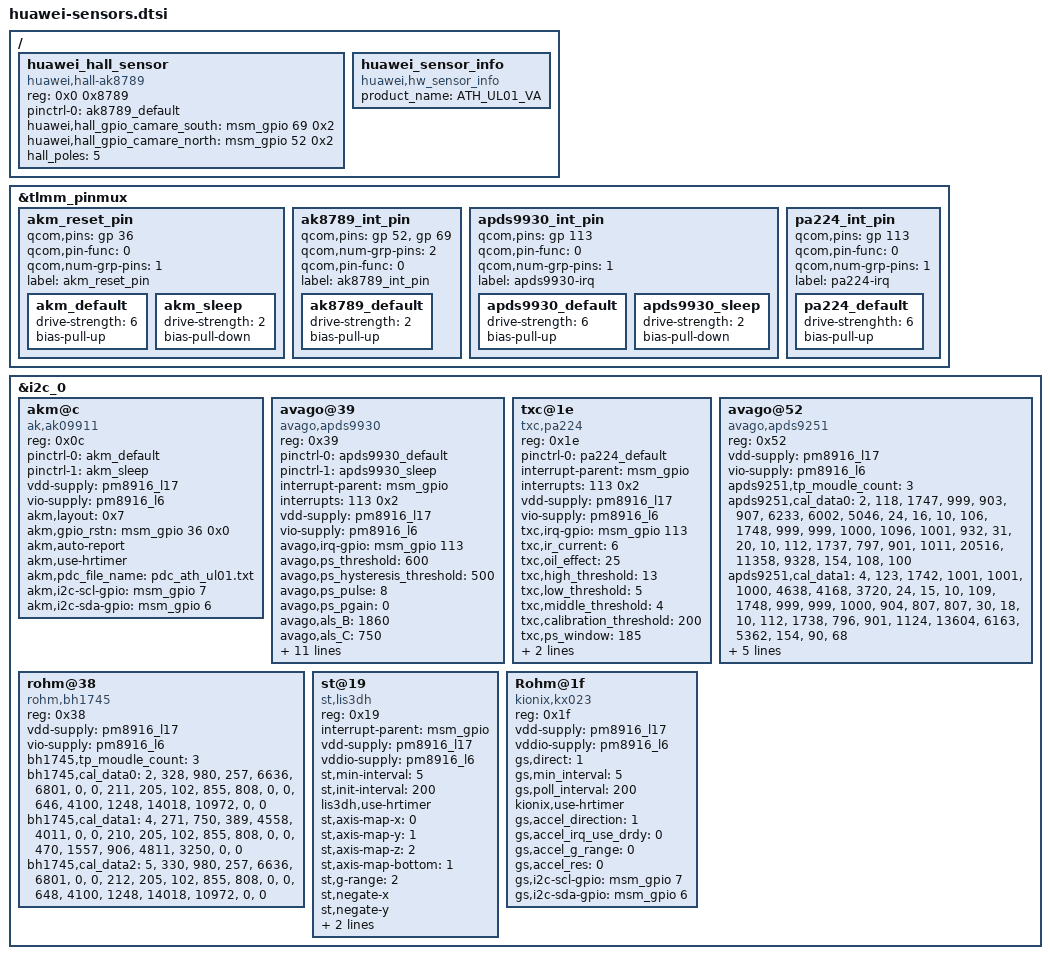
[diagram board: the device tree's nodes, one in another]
/*use fromdos convert file format to linux*/
/* Copyright (c) 2013 The Linux Foundation. All rights reserved.
 *
 * This program is free software; you can redistribute it and/or modify
 * it under the terms of the GNU General Public License version 2 and
 * only version 2 as published by the Free Software Foundation.
 *
 * This program is distributed in the hope that it will be useful,
 * but WITHOUT ANY WARRANTY; without even the implied warranty of
 * MERCHANTABILITY or FITNESS FOR A PARTICULAR PURPOSE.  See the
 * GNU General Public License for more details.
 */
&tlmm_pinmux {
	akm_reset_pin {
		qcom,pins = <&gp 36>;
		qcom,pin-func = <0>;
		qcom,num-grp-pins = <1>;
		label = "akm_reset_pin";
		akm_default: akm_default {
			drive-strength = <6>;
			bias-pull-up;
		};
		akm_sleep: akm_sleep {
			drive-strength = <2>;
			bias-pull-down;
		};
	};

	ak8789_int_pin {
		qcom,pins = <&gp 52>, <&gp 69>;
		qcom,num-grp-pins = <2>;
		qcom,pin-func = <0>;
		label = "ak8789_int_pin";
		ak8789_default: ak8789_default {
			  drive-strength = <2>;
			  bias-pull-up;
		};
	};
	apds9930_int_pin {
		qcom,pins = <&gp 113>;
		qcom,pin-func = <0>;
		qcom,num-grp-pins = <1>;
		label = "apds9930-irq";
		apds9930_default: apds9930_default {
			drive-strength = <6>;
			bias-pull-up;
		};
		apds9930_sleep: apds9930_sleep {
			drive-strength = <2>;
			bias-pull-down;
		};
	};
	pa224_int_pin {
		qcom,pins = <&gp 113>;
		qcom,pin-func = <0>;
		qcom,num-grp-pins = <1>;
		label = "pa224-irq";
		pa224_default: pa224_default {
			drive-strenghth = <6>;
			bias-pull-up;
		};
	};
};

&i2c_0 { /* BLSP1 QUP2 */
	akm@c {
		compatible = "ak,ak09911";
		reg = <0x0c>;
		pinctrl-names = "default","sleep";
		pinctrl-0 = <&akm_default>;
		pinctrl-1 = <&akm_sleep>;
		vdd-supply = <&pm8916_l17>;
		vio-supply = <&pm8916_l6>;
		akm,layout = <0x7>;
		akm,gpio_rstn = <&msm_gpio 36 0x0>;
		akm,auto-report;
		akm,use-hrtimer;
		akm,pdc_file_name = "pdc_ath_ul01.txt";
		akm,i2c-scl-gpio = <&msm_gpio 7 0x0>;
		akm,i2c-sda-gpio = <&msm_gpio 6 0x0>;
	};

	avago@39 {
		compatible = "avago,apds9930";
		reg = <0x39>;
		pinctrl-names = "default","sleep";
		pinctrl-0 = <&apds9930_default>;
		pinctrl-1 = <&apds9930_sleep>;
		interrupt-parent = <&msm_gpio>;
		interrupts = <113 0x2>;
		vdd-supply = <&pm8916_l17>;
		vio-supply = <&pm8916_l6>;
		avago,irq-gpio = <&msm_gpio 113 0x2>;
		avago,ps_threshold = <600>;
		avago,ps_hysteresis_threshold = <500>;
		avago,ps_pulse = <8>;
		avago,ps_pgain = <0>;
		avago,als_B = <1860>;
		avago,als_C = <750>;
		avago,als_D = <1290>;
		avago,ga_value = <48>;
	        avago,ga_a_value = <112>;
		avago,ga_c_value = <450>;
		avago,ga_d_value = <162>;
		avago,window = <110>;
		avago,wave = <84>;
		avago,ga_e_value = <220>;
		avago,ga_f_value = <43>;
		avago,i2c-scl-gpio = <&msm_gpio 7 0x0>;
		avago,i2c-sda-gpio = <&msm_gpio 6 0x0>;
	};
	txc@1e {
		compatible = "txc,pa224";
		reg = <0x1e>;
		pinctrl-names = "default";
		pinctrl-0 = <&pa224_default>;
		interrupt-parent = <&msm_gpio>;
		interrupts = <113 0x2>;
		vdd-supply = <&pm8916_l17>;
		vio-supply = <&pm8916_l6>;
		txc,irq-gpio = <&msm_gpio 113 0x2>;
		/*IR CURRENT 10MA*/
		txc,ir_current = <6>;
		txc,oil_effect = <25>;
		txc,high_threshold = <13>;
		txc,low_threshold = <5>;
		txc,middle_threshold = <4>;
		txc,calibration_threshold = <200>;
		txc,ps_window = <185>;
		txc,ps_wave = <20>;
		txc,ps_defalt_crosstalk = <50>;
	};
	avago@52 {
		compatible = "avago,apds9251";
		reg = <0x52>;
		vdd-supply = <&pm8916_l17>;
		vio-supply = <&pm8916_l6>;
		apds9251,tp_moudle_count = <3>;
		/*[module_id] [CCT_M] [CCT_N] [H] [A] [D] [LUX_P] [LUX_Q] [LUX_R] [cofficient0] [cofficient1] [cofficient2]*/
		apds9251,cal_data0 = "2","118","1747","999","903","907","6233","6002","5046","24","16","10",
		/*[CCT_M] [CCT_N] [H] [A] [D] [LUX_P] [LUX_Q] [LUX_R] [cofficient0] [cofficient1] [cofficient2]*/
		"106","1748","999","999","1000","1096","1001","932","31","20","10",
		/*[CCT_M] [CCT_N] [H] [A] [D] [LUX_P] [LUX_Q] [LUX_R] [cofficient0] [cofficient1] [cofficient2]*/
		"112","1737","797","901","1011","20516","11358","9328","154","108","100";
		/*[module_id] [CCT_M] [CCT_N] [H] [A] [D] [LUX_P] [LUX_Q] [LUX_R] [cofficient0] [cofficient1] [cofficient2]*/
		apds9251,cal_data1 = "4","123","1742","1001","1001","1000","4638","4168","3720","24","15","10",
		/*[CCT_M] [CCT_N] [H] [A] [D] [LUX_P] [LUX_Q] [LUX_R] [cofficient0] [cofficient1] [cofficient2]*/
		"109","1748","999","999","1000","904","807","807","30","18","10",
		/*[CCT_M] [CCT_N] [H] [A] [D] [LUX_P] [LUX_Q] [LUX_R] [cofficient0] [cofficient1] [cofficient2]*/
		"112","1738","796","901","1124","13604","6163","5362","154","90","68";
		/*[module_id] [CCT_M] [CCT_N] [H] [A] [D] [LUX_P] [LUX_Q] [LUX_R] [cofficient0] [cofficient1] [cofficient2]*/
		apds9251,cal_data2 = "5","9976","1490","948","1048","1150","2470","2475","2261","25","15","10",
		/*[CCT_M] [CCT_N] [H] [A] [D] [LUX_P] [LUX_Q] [LUX_R] [cofficient0] [cofficient1] [cofficient2]*/
		"6491","1636","946","1054","1159","1043","1004","940","30","19","10",
		/*[CCT_M] [CCT_N] [H] [A] [D] [LUX_P] [LUX_Q] [LUX_R] [cofficient0] [cofficient1] [cofficient2]*/
		"14588","1008","939","1211","1256","13043","11270","9600","58","25","10";
	};
	rohm@38 {
		compatible = "rohm,bh1745";
		reg = <0x38>;
		vdd-supply = <&pm8916_l17>;
		vio-supply = <&pm8916_l6>;
		bh1745,tp_moudle_count = <3>;
		/*JDI [module_id] [golden judge] r[0] r[1] g[0] g[1] b[0] b[1]*/
		bh1745,cal_data0 = "2","328","980","257","6636","6801","0","0",
		/*[white judge] r[0] r[1] g[0]  g[1] b[0] b[1]*/
		"211","205","102","855","808","0","0",
		/*[blue judge] r[0] r[1] g[0] g[1] b[0] b[1]*/
		"646","4100","1248","14018","10972","0","0";
		/*BOE [module_id] [golden judge] r[0] r[1] g[0] g[1] b[0] b[1]*/
		bh1745,cal_data1 = "4","271","750","389","4558","4011","0","0",
		/*[white judge] r[0] r[1] g[0]  g[1] b[0] b[1]*/
		"210","205","102","855","808","0","0",
		/*[blue judge] r[0] r[1] g[0] g[1] b[0] b[1]*/
		"470","1557","906","4811","3250","0","0";
		/*LG [module_id] [golden judge] r[0] r[1] g[0] g[1] b[0] b[1]*/
		bh1745,cal_data2 = "5","330","980","257","6636","6801","0","0",
		/*[white judge] r[0] r[1] g[0]  g[1] b[0] b[1]*/
		"212","205","102","855","808","0","0",
		/*[blue judge] r[0] r[1] g[0] g[1] b[0] b[1]*/
		"648","4100","1248","14018","10972","0","0";
	};

	st@19 {
		compatible = "st,lis3dh";
		reg = <0x19>;
		interrupt-parent = <&msm_gpio>;
		vdd-supply = <&pm8916_l17>;
		vddio-supply = <&pm8916_l6>;
		st,min-interval = <5>;
		st,init-interval = <200>;
		lis3dh,use-hrtimer;
		st,axis-map-x = <0>;
		st,axis-map-y = <1>;
		st,axis-map-z = <2>;
		/*1 is bottom and others means top*/
		st,axis-map-bottom=<1>;
		st,g-range = <2>;
		st,negate-x;
		st,negate-y;
		st,i2c-scl-gpio = <&msm_gpio 7 0x0>;
		st,i2c-sda-gpio = <&msm_gpio 6 0x0>;
	};
	Rohm@1f {
		compatible = "kionix,kx023";
		reg = <0x1f>;
		vdd-supply = <&pm8916_l17>;
		vddio-supply = <&pm8916_l6>;
		/*1 is bottom and others means top*/
		gs,direct = <1>;
		gs,min_interval = <5>;
		gs,poll_interval = <200>;
		kionix,use-hrtimer;
		gs,accel_direction = <1>;
		gs,accel_irq_use_drdy = <0>;
		gs,accel_g_range = <0>;
		gs,accel_res = <0>;
		gs,i2c-scl-gpio = <&msm_gpio 7 0x0>;
		gs,i2c-sda-gpio = <&msm_gpio 6 0x0>;
	};
};
/{
	huawei_hall_sensor{
		compatible = "huawei,hall-ak8789";
		reg = <0x0 0x8789>;
		pinctrl-names = "default";
		pinctrl-0 = <&ak8789_default>;
		huawei,hall_gpio_camare_south = <&msm_gpio 69 0x2>;
		huawei,hall_gpio_camare_north = <&msm_gpio 52 0x2>;
		hall_poles = <5>;
		status = "ok";
	};
};
/{
	huawei_sensor_info {
		compatible = "huawei,hw_sensor_info";
		product_name = "ATH_UL01_VA";
	};
};
